# GPIOMUX_INTRTR0_INTR_ROUTER_CFG register map
Vendor: Texas Instruments
Peripheral module from a debugger description file (folder J7VCL).
Registers are 32-bit, read-only, reset values left out (the file's numbers can be read two ways) unless marked. A register's access mark holds for its fields unless they carry their own. Offsets are as the file gives them; lines under a group give offsets from that group; [hi:lo] are bit positions; {n}, {i} and the like mark numbered series; 'fields as' and 'values as' point back to an identical list; <NAME> marks a mode.

## GPIOMUX_INTRTR0_INTR_ROUTER_CFG
0x00 GPIOMUX_INTRTR0_PID — Peripheral identification register. Uniquely identifies the module and its specific revision.
  [31:0] REV — TI internal data. Identifies revision of peripheral.
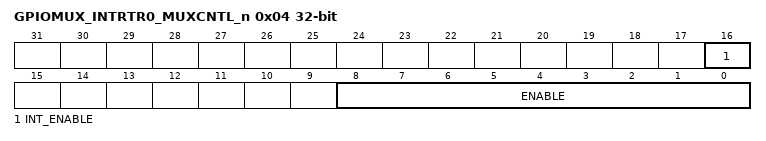
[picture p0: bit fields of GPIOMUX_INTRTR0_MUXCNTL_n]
0x04 GPIOMUX_INTRTR0_MUXCNTL_n access per field — Interrupt mux control register. Offset = 4h + (n * 4h); where n = 0h to 3Fh.
  [16] INT_ENABLE rw — Enable for interrupt output N
  [8:0] ENABLE rw — Mux control for interrupt output N
